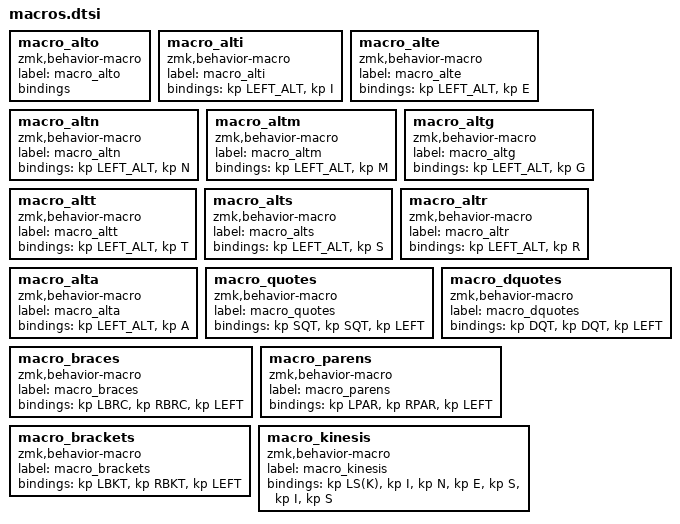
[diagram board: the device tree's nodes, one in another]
macro_alto: macro_alto{
compatible = "zmk,behavior-macro";
label = "macro_alto";
#binding-cells = <0>;
bindings = ;
};
macro_alti: macro_alti{
compatible = "zmk,behavior-macro";
label = "macro_alti";
#binding-cells = <0>;
bindings = <&kp LEFT_ALT>, <&kp I>;
};
macro_alte: macro_alte{
compatible = "zmk,behavior-macro";
label = "macro_alte";
#binding-cells = <0>;
bindings = <&kp LEFT_ALT>, <&kp E>;
};
macro_altn: macro_altn{
compatible = "zmk,behavior-macro";
label = "macro_altn";
#binding-cells = <0>;
bindings = <&kp LEFT_ALT>, <&kp N>;
};
macro_altm: macro_altm{
compatible = "zmk,behavior-macro";
label = "macro_altm";
#binding-cells = <0>;
bindings = <&kp LEFT_ALT>, <&kp M>;
};
macro_altg: macro_altg{
compatible = "zmk,behavior-macro";
label = "macro_altg";
#binding-cells = <0>;
bindings = <&kp LEFT_ALT>, <&kp G>;
};
macro_altt: macro_altt{
compatible = "zmk,behavior-macro";
label = "macro_altt";
#binding-cells = <0>;
bindings = <&kp LEFT_ALT>, <&kp T>;
};
macro_alts: macro_alts{
compatible = "zmk,behavior-macro";
label = "macro_alts";
#binding-cells = <0>;
bindings = <&kp LEFT_ALT>, <&kp S>;
};
macro_altr: macro_altr{
compatible = "zmk,behavior-macro";
label = "macro_altr";
#binding-cells = <0>;
bindings = <&kp LEFT_ALT>, <&kp R>;
};
macro_alta: macro_alta{
compatible = "zmk,behavior-macro";
label = "macro_alta";
#binding-cells = <0>;
bindings = <&kp LEFT_ALT>, <&kp A>;
};
macro_quotes: macro_quotes{
compatible = "zmk,behavior-macro";
label = "macro_quotes";
#binding-cells = <0>;
bindings = <&kp SQT>, <&kp SQT>, <&kp LEFT>;
};
macro_dquotes: macro_dquotes{
compatible = "zmk,behavior-macro";
label = "macro_dquotes";
#binding-cells = <0>;
bindings = <&kp DQT>, <&kp DQT>, <&kp LEFT>;
};
macro_braces: macro_braces{
compatible = "zmk,behavior-macro";
label = "macro_braces";
#binding-cells = <0>;
bindings = <&kp LBRC>, <&kp RBRC>, <&kp LEFT>;
};
macro_parens: macro_parens{
compatible = "zmk,behavior-macro";
label = "macro_parens";
#binding-cells = <0>;
bindings = <&kp LPAR>, <&kp RPAR>, <&kp LEFT>;
};
macro_brackets: macro_brackets{
compatible = "zmk,behavior-macro";
label = "macro_brackets";
#binding-cells = <0>;
bindings = <&kp LBKT>, <&kp RBKT>, <&kp LEFT>;
};
macro_kinesis: macro_kinesis{
compatible = "zmk,behavior-macro";
label = "macro_kinesis";
#binding-cells = <0>;
bindings = <&kp LS(K)>, <&kp I>, <&kp N>, <&kp E>, <&kp S>, <&kp I>, <&kp S>;
};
